AUTOSAR XML (schema 314)
package /ComponentType
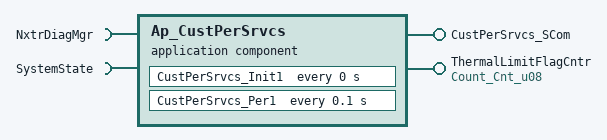
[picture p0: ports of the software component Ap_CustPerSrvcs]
  application software component type Ap_CustPerSrvcs
    provide port CustPerSrvcs_SCom: provided-interface=CustPerSrvcs_SCom
      provided-com-specs:
        operation=ReadActivePullParam, queue-length=1
        operation=ReadLrnEOTParam, queue-length=1
        operation=ResetThrmlCntr, queue-length=1
    provide port ThermalLimitFlagCntr: unqueued-sender-com-spec{data-element=Cnt_u08, can-invalidate=false, init-value=D_ZERO_CNT_U8}, provided-interface=Count_Cnt_u08
    require port NxtrDiagMgr: required-com-specs=[GetNTCActive, GetNTCFailed, GetNTCStatus, SetNTCStatus], required-interface=NxtrDiagMgr
    require port SystemState: required-interface=SystemState
  internal behavior Ap_CustPerSrvcs_InternalBehavior: component=Ap_CustPerSrvcs
    timing event CustPerSrvcs_Init1_InitEvent: start-on-event=CustPerSrvcs_Init1, period=0
    timing event TMT_CustPerSrvcs_Per1: start-on-event=CustPerSrvcs_Per1, period=0.1
    operation invoked event OIT_CustPerSrvcs_SCom_ReadActivePullParam_CustPerSrvcs_SCom_ReadActivePullParam: start-on-event=CustPerSrvcs_SCom_ReadActivePullParam, operation=CustPerSrvcs_SCom.ReadActivePullParam
    operation invoked event OIT_CustPerSrvcs_SCom_ReadLrnEOTParam_CustPerSrvcs_SCom_ReadLrnEOTParam: start-on-event=CustPerSrvcs_SCom_ReadLrnEOTParam, operation=CustPerSrvcs_SCom.ReadLrnEOTParam
    operation invoked event OIT_CustPerSrvcs_SCom_ResetThrmlCntr_CustPerSrvcs_SCom_ResetThrmlCntr: start-on-event=CustPerSrvcs_SCom_ResetThrmlCntr, operation=CustPerSrvcs_SCom.ResetThrmlCntr
    mode switch event MST_CustPerSrvcs_Trns1_0: start-on-event=CustPerSrvcs_Trns1, activation=ENTRY, mode=SystemState.Mode.OFF
    port-api-options:
      enable-take-address=false, indirect-api=false, port=CustPerSrvcs_SCom
      enable-take-address=false, indirect-api=false, port=NxtrDiagMgr
      enable-take-address=false, indirect-api=false, port=SystemState
      enable-take-address=false, indirect-api=false, port=ThermalLimitFlagCntr
    6 x runnable:
      CustPerSrvcs_Init1
      CustPerSrvcs_Per1
        data write access WRITE_ThermalLimitFlagCntr_Cnt_u08: data-element=ThermalLimitFlagCntr.Cnt_u08
        sync call SC_NxtrDiagMgr_GetNTCStatus: operation=NxtrDiagMgr.GetNTCStatus, timeout=0
      CustPerSrvcs_SCom_ReadActivePullParam
      CustPerSrvcs_SCom_ReadLrnEOTParam
      CustPerSrvcs_SCom_ResetThrmlCntr
      CustPerSrvcs_Trns1
  swc implementation Ap_CustPerSrvcs_Implementation: behavior=Ap_CustPerSrvcs_InternalBehavior
    code-descriptors:
      code Code: type=SRC
